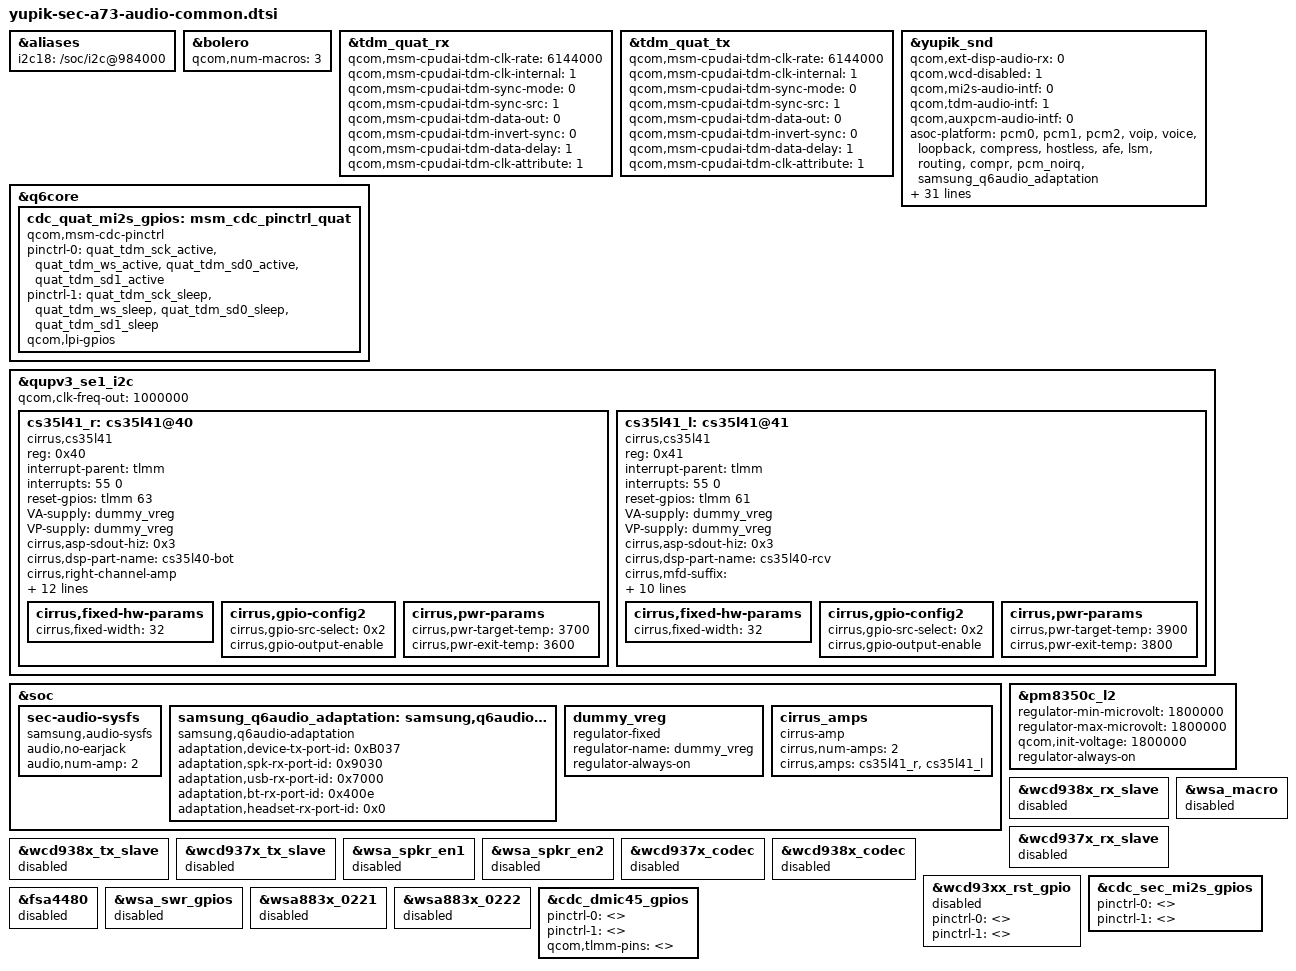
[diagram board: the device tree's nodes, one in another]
/* Copyright (c) 2019, The Linux Foundation. All rights reserved.
 *
 * This program is free software; you can redistribute it and/or modify
 * it under the terms of the GNU General Public License version 2 and
 * only version 2 as published by the Free Software Foundation.
 *
 * This program is distributed in the hope that it will be useful,
 * but WITHOUT ANY WARRANTY; without even the implied warranty of
 * MERCHANTABILITY or FITNESS FOR A PARTICULAR PURPOSE.  See the
 * GNU General Public License for more details.
 */

&aliases {
	i2c18 = "/soc/i2c@984000";
};

&bolero {
	qcom,num-macros = <3>;
};

&tdm_quat_rx {
	qcom,msm-cpudai-tdm-clk-rate = <6144000>;
	qcom,msm-cpudai-tdm-clk-internal = <1>;
	qcom,msm-cpudai-tdm-sync-mode = <0>;
	qcom,msm-cpudai-tdm-sync-src = <1>;
	qcom,msm-cpudai-tdm-data-out = <0>;
	qcom,msm-cpudai-tdm-invert-sync = <0>;
	qcom,msm-cpudai-tdm-data-delay = <1>;
	qcom,msm-cpudai-tdm-clk-attribute = /bits/ 16 <1>;
};

&tdm_quat_tx {
	qcom,msm-cpudai-tdm-clk-rate = <6144000>;
	qcom,msm-cpudai-tdm-clk-internal = <1>;
	qcom,msm-cpudai-tdm-sync-mode = <0>;
	qcom,msm-cpudai-tdm-sync-src = <1>;
	qcom,msm-cpudai-tdm-data-out = <0>;
	qcom,msm-cpudai-tdm-invert-sync = <0>;
	qcom,msm-cpudai-tdm-data-delay = <1>;
	qcom,msm-cpudai-tdm-clk-attribute = /bits/ 16 <1>;
};

&yupik_snd {
	qcom,ext-disp-audio-rx = <0>;
	qcom,wcd-disabled = <1>;
	qcom,mi2s-audio-intf = <0>;
	qcom,tdm-audio-intf = <1>;
	qcom,auxpcm-audio-intf = <0>;

	asoc-platform = <&pcm0>, <&pcm1>, <&pcm2>, <&voip>, <&voice>,
			<&loopback>, <&compress>, <&hostless>,
			<&afe>, <&lsm>, <&routing>, <&compr>,
			<&pcm_noirq>, <&samsung_q6audio_adaptation>;
	asoc-platform-names = "msm-pcm-dsp.0", "msm-pcm-dsp.1",
			"msm-pcm-dsp.2", "msm-voip-dsp",
			"msm-pcm-voice", "msm-pcm-loopback",
			"msm-compress-dsp", "msm-pcm-hostless",
			"msm-pcm-afe", "msm-lsm-client",
			"msm-pcm-routing", "msm-compr-dsp",
			"msm-pcm-dsp-noirq", "q6audio-adaptation";
	qcom,audio-routing =
		"TX DMIC0", "Digital Mic0",
		"TX DMIC1", "Digital Mic1",
		"TX DMIC2", "Digital Mic2",
		"TX DMIC3", "Digital Mic3",
		"TX DMIC4", "Digital Mic4",
		"TX DMIC5", "Digital Mic5",
		"VA DMIC0", "Digital Mic0",
		"VA DMIC1", "Digital Mic1",
		"VA DMIC2", "Digital Mic2",
		"VA DMIC3", "Digital Mic3",
		"VA DMIC4", "Digital Mic4",
		"VA DMIC5", "Digital Mic5",
		"AMP0 SPK", "Left AMP SPK",
		"AMP1 SPK", "Right AMP SPK";
	qcom,msm-mbhc-hphl-swh = <0>;
	qcom,msm-mbhc-gnd-swh = <0>;
	qcom,wsa-max-devs = <0>;
	qcom,wsa-devs = <0>;
	qcom,codec-max-aux-devs = <0>;
	qcom,codec-aux-devs = <>;
	fsa4480-i2c-handle = <>;
	qcom,cdc-dmic01-gpios = <&cdc_dmic01_gpios>;
	qcom,cdc-dmic23-gpios = <&cdc_dmic23_gpios>;
	qcom,cdc-dmic45-gpios = <>;
	qcom,quat-mi2s-gpios = <&cdc_quat_mi2s_gpios>;
	qcom,sec-mi2s-gpios = <>;
	qcom,tdm-max-slots = <4>;
	qcom,codec-conf = <0x12>; /* CS35L41 stereo*/
};

&q6core {
	cdc_quat_mi2s_gpios: msm_cdc_pinctrl_quat {
		compatible = "qcom,msm-cdc-pinctrl";
		pinctrl-names = "aud_active", "aud_sleep";
		pinctrl-0 = <&quat_tdm_sck_active &quat_tdm_ws_active
				 &quat_tdm_sd0_active &quat_tdm_sd1_active>;
		pinctrl-1 = <&quat_tdm_sck_sleep &quat_tdm_ws_sleep
				 &quat_tdm_sd0_sleep &quat_tdm_sd1_sleep>;
		qcom,lpi-gpios;
		#gpio-cells = <0>;
	};
};

&qupv3_se1_i2c {
	qcom,clk-freq-out = <1000000>;
	status = "ok";

	/* For Cirrus AMP (CS35L41)*/
	cs35l41_r: cs35l41@40 {
		#sound-dai-cells = <1>;
		compatible = "cirrus,cs35l41";
		reg = <0x40>;
		interrupt-parent = <&tlmm>;
		interrupts = <55 0>;
		reset-gpios = <&tlmm 63 0>;
		VA-supply = <&dummy_vreg>;
		VP-supply = <&dummy_vreg>;
		cirrus,asp-sdout-hiz = <0x3>;

		cirrus,dsp-part-name = "cs35l40-bot";
		cirrus,right-channel-amp;
		cirrus,mfd-suffix = "_r";
		cirrus,bd-suffix = "_1";
		cirrus,use-fsync-errata;
		cirrus,bd-max-temp = <110>;

		cirrus,dsp-noise-gate-enable;
		cirrus,dsp-noise-gate-delay = <0x4>;
		cirrus,dsp-noise-gate-threshold = <0x6>;

		cirrus,hw-noise-gate-select = <0x3F>;
		cirrus,hw-noise-gate-delay = <0x4>;
		cirrus,hw-noise-gate-threshold = <0x6>;
		cirrus,boost-peak-milliamp = <4100>;

		pinctrl-names = "default";
		pinctrl-0 = <&cs35l41_gpio_default>;

		cirrus,fixed-hw-params	{
			cirrus,fixed-width = <32>;
		};

		cirrus,gpio-config2 {
			cirrus,gpio-src-select = <0x2>;
			cirrus,gpio-output-enable;
		};

		cirrus,pwr-params {
			cirrus,pwr-target-temp = <3700>;
			cirrus,pwr-exit-temp = <3600>;
		};
	};

	cs35l41_l: cs35l41@41 {
		#sound-dai-cells = <1>;
		compatible = "cirrus,cs35l41";
		reg = <0x41>;
		interrupt-parent = <&tlmm>;
		interrupts = <55 0>;
		reset-gpios = <&tlmm 61 0>;
		VA-supply = <&dummy_vreg>;
		VP-supply = <&dummy_vreg>;
		cirrus,asp-sdout-hiz = <0x3>;

		cirrus,dsp-part-name = "cs35l40-rcv";
		cirrus,mfd-suffix = "";
		cirrus,bd-suffix = "_0";
		cirrus,use-fsync-errata;
		cirrus,bd-max-temp = <100>;

		cirrus,dsp-noise-gate-enable;
		cirrus,dsp-noise-gate-delay = <0x4>;
		cirrus,dsp-noise-gate-threshold = <0x6>;

		cirrus,hw-noise-gate-select = <0x3F>;
		cirrus,hw-noise-gate-delay = <0x4>;
		cirrus,hw-noise-gate-threshold = <0x6>;
		cirrus,boost-peak-milliamp = <4100>;

		cirrus,fixed-hw-params	{
			cirrus,fixed-width = <32>;
		};

		cirrus,gpio-config2 {
			cirrus,gpio-src-select = <0x2>;
			cirrus,gpio-output-enable;
		};

		cirrus,pwr-params {
			cirrus,pwr-target-temp = <3900>;
			cirrus,pwr-exit-temp = <3800>;
		};
	};
};

&soc {
	sec-audio-sysfs {
		compatible = "samsung,audio-sysfs";
		status = "okay";
		audio,no-earjack;
		audio,num-amp = <2>;
	};

	samsung_q6audio_adaptation: samsung,q6audio-adaptation {
		compatible = "samsung,q6audio-adaptation";
		adaptation,device-tx-port-id = <0xB037>;
		adaptation,spk-rx-port-id = <0x9030>;
		adaptation,usb-rx-port-id = <0x7000>;
		adaptation,bt-rx-port-id = <0x400e>;
		adaptation,headset-rx-port-id = <0x0>;
	};

	dummy_vreg: dummy_vreg {
		compatible = "regulator-fixed";
		status = "ok";
		regulator-name = "dummy_vreg";
		regulator-always-on;
	};

	cirrus_amps {
		compatible = "cirrus-amp";
		cirrus,num-amps = <2>;
		cirrus,amps = <&cs35l41_r &cs35l41_l>;
	};
};

&pm8350c_l2  {
	regulator-min-microvolt = <1800000>;
	regulator-max-microvolt = <1800000>;
	qcom,init-voltage = <1800000>;
	regulator-always-on;
};

&wcd938x_rx_slave {
	status = "disabled";
};

&wcd937x_rx_slave {
	status = "disabled";
};

&wcd938x_tx_slave {
	status = "disabled";
};

&wcd937x_tx_slave {
	status = "disabled";
};

&wsa_macro {
	status = "disabled";
};

&wsa_spkr_en1 {
	status = "disabled";
};

&wsa_spkr_en2 {
	status = "disabled";
};

&wcd937x_codec {
	status = "disabled";
};

&wcd938x_codec {
	status = "disabled";
};

&wcd93xx_rst_gpio {
	status = "disabled";
	pinctrl-0 = <>;
	pinctrl-1 = <>;
};

&cdc_sec_mi2s_gpios {
	pinctrl-0 = <>;
	pinctrl-1 = <>;
};

&fsa4480 {
	status = "disabled";
};

&wsa_swr_gpios {
	status = "disabled";
};

&wsa883x_0221 {
	status = "disabled";
};

&wsa883x_0222 {
	status = "disabled";
};

&cdc_dmic45_gpios {
	pinctrl-0 = <>;
	pinctrl-1 = <>;
	qcom,tlmm-pins = <>;
};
